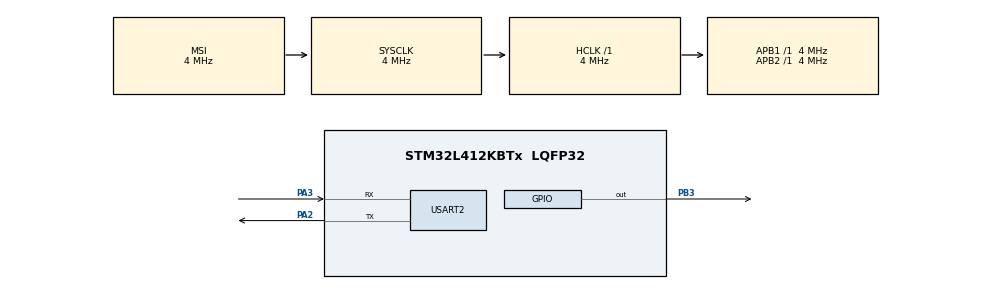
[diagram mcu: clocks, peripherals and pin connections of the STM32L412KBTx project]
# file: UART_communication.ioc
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Mcu.Family=STM32L4
Mcu.Name=STM32L412KBTx
Mcu.Package=LQFP32
NVIC.PriorityGroup=NVIC_PRIORITYGROUP_4
PA0-CK_IN.Mode=HSE-External-Clock-Source-for-LittleOrca
PA0-CK_IN.Signal=RCC_CK_IN
PA13\ (JTMS/SWDIO).Mode=Serial_Wire
PA13\ (JTMS/SWDIO).Signal=SYS_JTMS-SWDIO
PA14\ (JTCK/SWCLK).Mode=Serial_Wire
PA14\ (JTCK/SWCLK).Signal=SYS_JTCK-SWCLK
PA2.Mode=Asynchronous
PA2.Signal=USART2_TX
PA3.Mode=Asynchronous
PA3.Signal=USART2_RX
PB3\ (JTDO/TRACESWO).Signal=GPIO_Output
ProjectManager.HeapSize=0x200
ProjectManager.StackSize=0x400
ProjectManager.TargetToolchain=STM32CubeIDE
RCC.ADCFreq_Value=4000000
RCC.AHBFreq_Value=4000000
RCC.APB1Freq_Value=4000000
RCC.APB1TimFreq_Value=4000000
RCC.APB2Freq_Value=4000000
RCC.APB2TimFreq_Value=4000000
RCC.CortexFreq_Value=4000000
RCC.HCLKFreq_Value=4000000
RCC.HSE_VALUE=8000000
RCC.HSI48_VALUE=48000000
RCC.HSI_VALUE=16000000
RCC.LSE_VALUE=32768
RCC.MSIAutoCalibration=DISABLED
RCC.MSI_VALUE=4000000
RCC.SYSCLKFreq_VALUE=4000000
RCC.USBFreq_Value=4000000
RCC.VCOOutputFreq_Value=32000000
USART2.VirtualMode-Asynchronous=VM_ASYNC
board=custom

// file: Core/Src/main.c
/* USER CODE BEGIN Header */
/**
  ******************************************************************************
  * @file           : main.c
  * @brief          : Demonstrates transmission of an ASCII pattern with a UART
  * 				  peripheral, while also blinking the on-board LED to show
  * 				  that the CPU does get blocked by the transmission, thus
  * 				  the blinking is delayed.
  *
  * 				  UART BaudRate: 115200
  *
  ******************************************************************************
  * @attention
  *
  * Copyright (c) 2024 STMicroelectronics.
  * All rights reserved.
  *
  * This software is licensed under terms that can be found in the LICENSE file
  * in the root directory of this software component.
  * If no LICENSE file comes with this software, it is provided AS-IS.
  *
  ******************************************************************************
  */
/* USER CODE END Header */
#include "main.h"

UART_HandleTypeDef huart2;

void SystemClock_Config(void);
static void MX_GPIO_Init(void);
static void MX_USART2_UART_Init(void);

/* USER CODE BEGIN 0 */

uint8_t data[2048];
uint8_t TxData[2048];
int countloop = 0;
int isSent = 1;

/* USER CODE END 0 */

int main(void)
{

  /* MCU Configuration--------------------------------------------------------*/

  /* Reset of all peripherals, Initializes the Flash interface and the Systick. */
  HAL_Init();

  /* Configure the system clock */
  SystemClock_Config();

  /* Initialize all configured peripherals */
  MX_GPIO_Init();
  MX_USART2_UART_Init();
  /* USER CODE BEGIN 2 */

  /* Fill data with ASCII chars: first half is '!' to '{' on new lines*/
  uint32_t j = 0;
  for (uint32_t i = 0; i < sizeof(TxData)/2; i++) {
	  j = i % 93;
	  // new line after each pattern and at end of all data
	  if (j == 91 || i == sizeof(TxData)/2-2) {
		  // '/r'
		  data[i] = 13;
		  // Also fill first half of transmit buffer
		  TxData[i] = 13;
	  } else if (j == 92 || i == sizeof(TxData)/2-1) {
		  // '/n'
		  data[i] = 10;
		  TxData[i] = 10;
	  } else {
		  data[i] = 33 + j;
		  TxData[i] = 33 + j;
	  }
  }

  /* Second half is '}' to '!' on new lines */
  for (uint32_t i = sizeof(TxData)/2; i < sizeof(TxData); i++) {
	  j = i % 93;
	  // new line after each pattern and at end of all data
	  if (j == 91 || i == sizeof(TxData)-2) {
		  // '/r'
		  data[i] = 13;
	  } else if (j == 92 || i == sizeof(TxData)-1) {
		  // '/n'
		  data[i] = 10;
	  } else {
		  data[i] = 123 - j;
	  }
  }

  /* USER CODE END 2 */

  /* Infinite loop */
  /* USER CODE BEGIN WHILE */
  while (countloop < 20)
  {
    /* USER CODE END WHILE */

    /* USER CODE BEGIN 3 */

	// Blocking transmit
	HAL_UART_Transmit(&huart2, TxData, sizeof(TxData), HAL_MAX_DELAY);

	HAL_GPIO_TogglePin(GPIOB, GPIO_PIN_3);
	HAL_Delay(300);
	countloop++;
  }
  /* USER CODE END 3 */
}

void SystemClock_Config(void)
{
  RCC_OscInitTypeDef RCC_OscInitStruct = {0};
  RCC_ClkInitTypeDef RCC_ClkInitStruct = {0};

  /** Configure the main internal regulator output voltage
  */
  if (HAL_PWREx_ControlVoltageScaling(PWR_REGULATOR_VOLTAGE_SCALE1) != HAL_OK)
  {
    Error_Handler();
  }
  /** Initializes the RCC Oscillators according to the specified parameters
  * in the RCC_OscInitTypeDef structure.
  */
  RCC_OscInitStruct.OscillatorType = RCC_OSCILLATORTYPE_MSI;
  RCC_OscInitStruct.MSIState = RCC_MSI_ON;
  RCC_OscInitStruct.MSICalibrationValue = 0;
  RCC_OscInitStruct.MSIClockRange = RCC_MSIRANGE_6;
  RCC_OscInitStruct.PLL.PLLState = RCC_PLL_NONE;
  if (HAL_RCC_OscConfig(&RCC_OscInitStruct) != HAL_OK)
  {
    Error_Handler();
  }
  /** Initializes the CPU, AHB and APB buses clocks
  */
  RCC_ClkInitStruct.ClockType = RCC_CLOCKTYPE_HCLK|RCC_CLOCKTYPE_SYSCLK
                              |RCC_CLOCKTYPE_PCLK1|RCC_CLOCKTYPE_PCLK2;
  RCC_ClkInitStruct.SYSCLKSource = RCC_SYSCLKSOURCE_MSI;
  RCC_ClkInitStruct.AHBCLKDivider = RCC_SYSCLK_DIV1;
  RCC_ClkInitStruct.APB1CLKDivider = RCC_HCLK_DIV1;
  RCC_ClkInitStruct.APB2CLKDivider = RCC_HCLK_DIV1;

  if (HAL_RCC_ClockConfig(&RCC_ClkInitStruct, FLASH_LATENCY_0) != HAL_OK)
  {
    Error_Handler();
  }
}

static void MX_USART2_UART_Init(void)
{

  huart2.Instance = USART2;
  huart2.Init.BaudRate = 115200;
  huart2.Init.WordLength = UART_WORDLENGTH_8B;
  huart2.Init.StopBits = UART_STOPBITS_1;
  huart2.Init.Parity = UART_PARITY_NONE;
  huart2.Init.Mode = UART_MODE_TX_RX;
  huart2.Init.HwFlowCtl = UART_HWCONTROL_NONE;
  huart2.Init.OverSampling = UART_OVERSAMPLING_16;
  huart2.Init.OneBitSampling = UART_ONE_BIT_SAMPLE_DISABLE;
  huart2.AdvancedInit.AdvFeatureInit = UART_ADVFEATURE_NO_INIT;
  if (HAL_UART_Init(&huart2) != HAL_OK)
  {
    Error_Handler();
  }

}

static void MX_GPIO_Init(void)
{
  GPIO_InitTypeDef GPIO_InitStruct = {0};

  /* GPIO Ports Clock Enable */
  __HAL_RCC_GPIOA_CLK_ENABLE();
  __HAL_RCC_GPIOB_CLK_ENABLE();

  /*Configure GPIO pin Output Level */
  HAL_GPIO_WritePin(GPIOB, GPIO_PIN_3, GPIO_PIN_RESET);

  /*Configure GPIO pin : PB3 */
  GPIO_InitStruct.Pin = GPIO_PIN_3;
  GPIO_InitStruct.Mode = GPIO_MODE_OUTPUT_PP;
  GPIO_InitStruct.Pull = GPIO_NOPULL;
  GPIO_InitStruct.Speed = GPIO_SPEED_FREQ_LOW;
  HAL_GPIO_Init(GPIOB, &GPIO_InitStruct);

}

void Error_Handler(void)
{
  __disable_irq();
  while (1)
  {
  }
}
